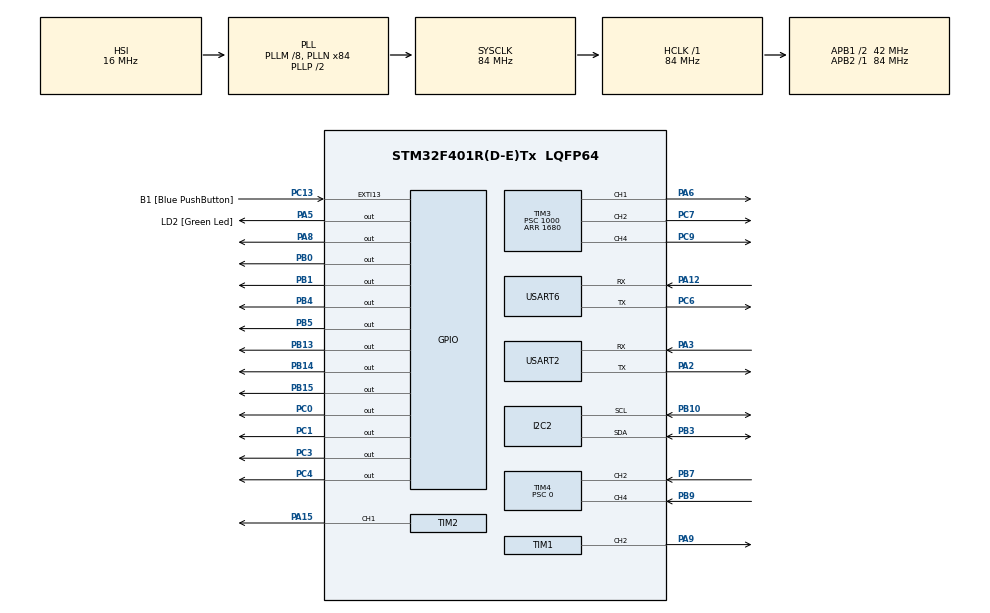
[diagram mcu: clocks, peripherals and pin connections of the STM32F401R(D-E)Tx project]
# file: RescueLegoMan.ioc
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Dma.Request0=TIM4_CH2
Dma.TIM4_CH2.0.Direction=DMA_PERIPH_TO_MEMORY
Dma.TIM4_CH2.0.FIFOMode=DMA_FIFOMODE_DISABLE
Dma.TIM4_CH2.0.Instance=DMA1_Stream3
Dma.TIM4_CH2.0.MemDataAlignment=DMA_MDATAALIGN_WORD
Dma.TIM4_CH2.0.MemInc=DMA_MINC_ENABLE
Dma.TIM4_CH2.0.Mode=DMA_NORMAL
Dma.TIM4_CH2.0.PeriphDataAlignment=DMA_PDATAALIGN_WORD
Dma.TIM4_CH2.0.PeriphInc=DMA_PINC_DISABLE
Dma.TIM4_CH2.0.Priority=DMA_PRIORITY_LOW
Mcu.Family=STM32F4
Mcu.Name=STM32F401R(D-E)Tx
Mcu.Package=LQFP64
NVIC.DMA1_Stream3_IRQn=true\:0\:0\:false\:false\:true\:false\:true
NVIC.EXTI15_10_IRQn=true\:0\:0\:false\:false\:true\:true\:true
NVIC.PriorityGroup=NVIC_PRIORITYGROUP_0
NVIC.TIM2_IRQn=true\:0\:0\:false\:false\:true\:true\:true
NVIC.TIM3_IRQn=true\:0\:0\:false\:false\:true\:true\:true
NVIC.TIM4_IRQn=true\:0\:0\:false\:false\:true\:true\:true
PA12.Mode=Asynchronous
PA12.Signal=USART6_RX
PA13.GPIO_Label=TMS
PA13.Mode=Serial_Wire
PA13.Signal=SYS_JTMS-SWDIO
PA14.GPIO_Label=TCK
PA14.Mode=Serial_Wire
PA14.Signal=SYS_JTCK-SWCLK
PA15.Signal=S_TIM2_CH1_ETR
PA2.Mode=Asynchronous
PA2.Signal=USART2_TX
PA3.Mode=Asynchronous
PA3.Signal=USART2_RX
PA5.GPIO_Label=LD2 [Green Led]
PA5.GPIO_Mode=GPIO_MODE_OUTPUT_PP
PA5.GPIO_PuPd=GPIO_NOPULL
PA5.GPIO_Speed=GPIO_SPEED_FREQ_LOW
PA5.Signal=GPIO_Output
PA6.Signal=S_TIM3_CH1
PA8.Signal=GPIO_Output
PA9.Signal=S_TIM1_CH2
PB0.Signal=GPIO_Output
PB1.Signal=GPIO_Output
PB10.Mode=I2C
PB10.Signal=I2C2_SCL
PB13.Signal=GPIO_Output
PB14.Signal=GPIO_Output
PB15.Signal=GPIO_Output
PB3.Mode=I2C
PB3.Signal=I2C2_SDA
PB4.Signal=GPIO_Output
PB5.Signal=GPIO_Output
PB7.Signal=S_TIM4_CH2
PB9.Signal=S_TIM4_CH4
PC0.Signal=GPIO_Output
PC1.Signal=GPIO_Output
PC13-ANTI_TAMP.GPIO_Label=B1 [Blue PushButton]
PC13-ANTI_TAMP.GPIO_ModeDefaultEXTI=GPIO_MODE_IT_FALLING
PC13-ANTI_TAMP.GPIO_PuPd=GPIO_NOPULL
PC13-ANTI_TAMP.Signal=GPXTI13
PC14-OSC32_IN.Mode=LSE-External-Oscillator
PC14-OSC32_IN.Signal=RCC_OSC32_IN
PC15-OSC32_OUT.Mode=LSE-External-Oscillator
PC15-OSC32_OUT.Signal=RCC_OSC32_OUT
PC3.Signal=GPIO_Output
PC4.Signal=GPIO_Output
PC6.Mode=Asynchronous
PC6.Signal=USART6_TX
PC7.Signal=S_TIM3_CH2
PC9.Signal=S_TIM3_CH4
PH0\ -\ OSC_IN.Mode=HSE-External-Clock-Source
PH0\ -\ OSC_IN.Signal=RCC_OSC_IN
PH1\ -\ OSC_OUT.Mode=HSE-External-Clock-Source
PH1\ -\ OSC_OUT.Signal=RCC_OSC_OUT
ProjectManager.HeapSize=0x200
ProjectManager.StackSize=0x400
ProjectManager.TargetToolchain=STM32CubeIDE
RCC.48MHZClocksFreq_Value=24000000
RCC.AHBFreq_Value=84000000
RCC.APB1CLKDivider=RCC_HCLK_DIV2
RCC.APB1Freq_Value=42000000
RCC.APB1TimFreq_Value=84000000
RCC.APB2Freq_Value=84000000
RCC.APB2TimFreq_Value=84000000
RCC.CortexFreq_Value=84000000
RCC.HCLKFreq_Value=84000000
RCC.HSE_VALUE=8000000
RCC.HSI_VALUE=16000000
RCC.PLLM=8
RCC.PLLN=84
RCC.PLLQ=7
RCC.SYSCLKFreq_VALUE=84000000
RCC.SYSCLKSource=RCC_SYSCLKSOURCE_PLLCLK
RCC.VCOOutputFreq_Value=168000000
SH.S_TIM1_CH2.0=TIM1_CH2,PWM Generation2 CH2
SH.S_TIM2_CH1_ETR.0=TIM2_CH1,PWM Generation1 CH1
SH.S_TIM3_CH1.0=TIM3_CH1,PWM Generation1 CH1
SH.S_TIM3_CH2.0=TIM3_CH2,PWM Generation2 CH2
SH.S_TIM3_CH4.0=TIM3_CH4,PWM Generation4 CH4
SH.S_TIM4_CH2.0=TIM4_CH2,Input_Capture2_from_TI2
SH.S_TIM4_CH4.0=TIM4_CH4,Input_Capture4_from_TI4
TIM1.AutoReloadPreload=TIM_AUTORELOAD_PRELOAD_ENABLE
TIM1.Channel-PWM\ Generation2\ CH2=TIM_CHANNEL_2
TIM1.Period=1680
TIM1.Prescaler=1000
TIM2.AutoReloadPreload=TIM_AUTORELOAD_PRELOAD_ENABLE
TIM2.Channel-PWM\ Generation1\ CH1=TIM_CHANNEL_1
TIM2.Period=1000
TIM2.Prescaler=1680
TIM3.AutoReloadPreload=TIM_AUTORELOAD_PRELOAD_ENABLE
TIM3.Channel-PWM\ Generation1\ CH1=TIM_CHANNEL_1
TIM3.Channel-PWM\ Generation2\ CH2=TIM_CHANNEL_2
TIM3.Channel-PWM\ Generation4\ CH4=TIM_CHANNEL_4
TIM3.Period=1680
TIM3.Prescaler=1000
TIM4.Channel-Input_Capture2_from_TI2=TIM_CHANNEL_2
TIM4.Channel-Input_Capture4_from_TI4=TIM_CHANNEL_4
TIM4.Period=0xffff
TIM4.Prescaler=0
USART2.VirtualMode=VM_ASYNC
USART6.VirtualMode=VM_ASYNC
VP_TIM2_VS_ClockSourceINT.Mode=Internal
board=NUCLEO-F401RE

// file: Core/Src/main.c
/* USER CODE BEGIN Header */
/**
  ******************************************************************************
  * @file           : main.c
  * @brief          : Main program body
  ******************************************************************************
  * @attention
  *
  * <h2><center>&copy; Copyright (c) 2021 STMicroelectronics.
  * All rights reserved.</center></h2>
  *
  * This software component is licensed by ST under BSD 3-Clause license,
  * the "License"; You may not use this file except in compliance with the
  * License. You may obtain a copy of the License at:
  *                        opensource.org/licenses/BSD-3-Clause
  *
  ******************************************************************************
  */
/* USER CODE END Header */
#include "main.h"

/* USER CODE BEGIN Includes */
#include <algorithm.h>
#include <colour_sensor.h>
#include <imu.h>
#include <motor.h>
#include <servo.h>
#include <test.h>

/* USER CODE END Includes */

I2C_HandleTypeDef hi2c2;

TIM_HandleTypeDef htim1;
TIM_HandleTypeDef htim2;
TIM_HandleTypeDef htim3;
TIM_HandleTypeDef htim4;
DMA_HandleTypeDef hdma_tim4_ch2;

UART_HandleTypeDef huart2;
UART_HandleTypeDef huart6;

void SystemClock_Config(void);
static void MX_GPIO_Init(void);
static void MX_USART2_UART_Init(void);
static void MX_TIM2_Init(void);
static void MX_TIM1_Init(void);
static void MX_TIM3_Init(void);
static void MX_TIM4_Init(void);
static void MX_USART6_UART_Init(void);
static void MX_DMA_Init(void);
static void MX_I2C2_Init(void);

int main(void)
{

  /* MCU Configuration--------------------------------------------------------*/

  /* Reset of all peripherals, Initializes the Flash interface and the Systick. */
  HAL_Init();

  /* Configure the system clock */
  SystemClock_Config();

  /* Initialize all configured peripherals */
  MX_GPIO_Init();
  MX_USART2_UART_Init();
  MX_TIM2_Init();
  MX_TIM1_Init();
  MX_TIM3_Init();
  MX_TIM4_Init();
  MX_USART6_UART_Init();
  MX_DMA_Init();
  MX_I2C2_Init();

  /* Infinite loop */
  /* USER CODE BEGIN WHILE */

//  initMotors(&htim1, &htim3);
//  initServo(&htim2);
//  initColourSensors(&htim4);
//  HAL_Delay(3000);
  init(&htim1, &htim3, &htim2, &htim4);
  searchAndRescue();

  while (1)
  {
    /* USER CODE END WHILE */

    /* USER CODE BEGIN 3 */
	  //testMotors();
//	  testServo();
	  //testImu(&hi2c2);
	  //testColourSensor();
  }
  /* USER CODE END 3 */
}

void SystemClock_Config(void)
{
  RCC_OscInitTypeDef RCC_OscInitStruct = {0};
  RCC_ClkInitTypeDef RCC_ClkInitStruct = {0};

  /** Configure the main internal regulator output voltage
  */
  __HAL_RCC_PWR_CLK_ENABLE();
  __HAL_PWR_VOLTAGESCALING_CONFIG(PWR_REGULATOR_VOLTAGE_SCALE2);
  /** Initializes the RCC Oscillators according to the specified parameters
  * in the RCC_OscInitTypeDef structure.
  */
  RCC_OscInitStruct.OscillatorType = RCC_OSCILLATORTYPE_HSI;
  RCC_OscInitStruct.HSIState = RCC_HSI_ON;
  RCC_OscInitStruct.HSICalibrationValue = RCC_HSICALIBRATION_DEFAULT;
  RCC_OscInitStruct.PLL.PLLState = RCC_PLL_ON;
  RCC_OscInitStruct.PLL.PLLSource = RCC_PLLSOURCE_HSI;
  RCC_OscInitStruct.PLL.PLLM = 8;
  RCC_OscInitStruct.PLL.PLLN = 84;
  RCC_OscInitStruct.PLL.PLLP = RCC_PLLP_DIV2;
  RCC_OscInitStruct.PLL.PLLQ = 7;
  if (HAL_RCC_OscConfig(&RCC_OscInitStruct) != HAL_OK)
  {
    Error_Handler();
  }
  /** Initializes the CPU, AHB and APB buses clocks
  */
  RCC_ClkInitStruct.ClockType = RCC_CLOCKTYPE_HCLK|RCC_CLOCKTYPE_SYSCLK
                              |RCC_CLOCKTYPE_PCLK1|RCC_CLOCKTYPE_PCLK2;
  RCC_ClkInitStruct.SYSCLKSource = RCC_SYSCLKSOURCE_PLLCLK;
  RCC_ClkInitStruct.AHBCLKDivider = RCC_SYSCLK_DIV1;
  RCC_ClkInitStruct.APB1CLKDivider = RCC_HCLK_DIV2;
  RCC_ClkInitStruct.APB2CLKDivider = RCC_HCLK_DIV1;

  if (HAL_RCC_ClockConfig(&RCC_ClkInitStruct, FLASH_LATENCY_2) != HAL_OK)
  {
    Error_Handler();
  }
}

static void MX_I2C2_Init(void)
{

  hi2c2.Instance = I2C2;
  hi2c2.Init.ClockSpeed = 100000;
  hi2c2.Init.DutyCycle = I2C_DUTYCYCLE_2;
  hi2c2.Init.OwnAddress1 = 0;
  hi2c2.Init.AddressingMode = I2C_ADDRESSINGMODE_7BIT;
  hi2c2.Init.DualAddressMode = I2C_DUALADDRESS_DISABLE;
  hi2c2.Init.OwnAddress2 = 0;
  hi2c2.Init.GeneralCallMode = I2C_GENERALCALL_DISABLE;
  hi2c2.Init.NoStretchMode = I2C_NOSTRETCH_DISABLE;
  if (HAL_I2C_Init(&hi2c2) != HAL_OK)
  {
    Error_Handler();
  }

}

static void MX_TIM1_Init(void)
{

  TIM_MasterConfigTypeDef sMasterConfig = {0};
  TIM_OC_InitTypeDef sConfigOC = {0};
  TIM_BreakDeadTimeConfigTypeDef sBreakDeadTimeConfig = {0};

  htim1.Instance = TIM1;
  htim1.Init.Prescaler = 1000;
  htim1.Init.CounterMode = TIM_COUNTERMODE_UP;
  htim1.Init.Period = 1680;
  htim1.Init.ClockDivision = TIM_CLOCKDIVISION_DIV1;
  htim1.Init.RepetitionCounter = 0;
  htim1.Init.AutoReloadPreload = TIM_AUTORELOAD_PRELOAD_ENABLE;
  if (HAL_TIM_PWM_Init(&htim1) != HAL_OK)
  {
    Error_Handler();
  }
  sMasterConfig.MasterOutputTrigger = TIM_TRGO_RESET;
  sMasterConfig.MasterSlaveMode = TIM_MASTERSLAVEMODE_DISABLE;
  if (HAL_TIMEx_MasterConfigSynchronization(&htim1, &sMasterConfig) != HAL_OK)
  {
    Error_Handler();
  }
  sConfigOC.OCMode = TIM_OCMODE_PWM1;
  sConfigOC.Pulse = 0;
  sConfigOC.OCPolarity = TIM_OCPOLARITY_HIGH;
  sConfigOC.OCNPolarity = TIM_OCNPOLARITY_HIGH;
  sConfigOC.OCFastMode = TIM_OCFAST_DISABLE;
  sConfigOC.OCIdleState = TIM_OCIDLESTATE_RESET;
  sConfigOC.OCNIdleState = TIM_OCNIDLESTATE_RESET;
  if (HAL_TIM_PWM_ConfigChannel(&htim1, &sConfigOC, TIM_CHANNEL_2) != HAL_OK)
  {
    Error_Handler();
  }
  sBreakDeadTimeConfig.OffStateRunMode = TIM_OSSR_DISABLE;
  sBreakDeadTimeConfig.OffStateIDLEMode = TIM_OSSI_DISABLE;
  sBreakDeadTimeConfig.LockLevel = TIM_LOCKLEVEL_OFF;
  sBreakDeadTimeConfig.DeadTime = 0;
  sBreakDeadTimeConfig.BreakState = TIM_BREAK_DISABLE;
  sBreakDeadTimeConfig.BreakPolarity = TIM_BREAKPOLARITY_HIGH;
  sBreakDeadTimeConfig.AutomaticOutput = TIM_AUTOMATICOUTPUT_DISABLE;
  if (HAL_TIMEx_ConfigBreakDeadTime(&htim1, &sBreakDeadTimeConfig) != HAL_OK)
  {
    Error_Handler();
  }
  HAL_TIM_MspPostInit(&htim1);

}

static void MX_TIM2_Init(void)
{

  TIM_ClockConfigTypeDef sClockSourceConfig = {0};
  TIM_MasterConfigTypeDef sMasterConfig = {0};
  TIM_OC_InitTypeDef sConfigOC = {0};

  htim2.Instance = TIM2;
  htim2.Init.Prescaler = 1680;
  htim2.Init.CounterMode = TIM_COUNTERMODE_UP;
  htim2.Init.Period = 1000;
  htim2.Init.ClockDivision = TIM_CLOCKDIVISION_DIV1;
  htim2.Init.AutoReloadPreload = TIM_AUTORELOAD_PRELOAD_ENABLE;
  if (HAL_TIM_Base_Init(&htim2) != HAL_OK)
  {
    Error_Handler();
  }
  sClockSourceConfig.ClockSource = TIM_CLOCKSOURCE_INTERNAL;
  if (HAL_TIM_ConfigClockSource(&htim2, &sClockSourceConfig) != HAL_OK)
  {
    Error_Handler();
  }
  if (HAL_TIM_PWM_Init(&htim2) != HAL_OK)
  {
    Error_Handler();
  }
  sMasterConfig.MasterOutputTrigger = TIM_TRGO_RESET;
  sMasterConfig.MasterSlaveMode = TIM_MASTERSLAVEMODE_DISABLE;
  if (HAL_TIMEx_MasterConfigSynchronization(&htim2, &sMasterConfig) != HAL_OK)
  {
    Error_Handler();
  }
  sConfigOC.OCMode = TIM_OCMODE_PWM1;
  sConfigOC.Pulse = 0;
  sConfigOC.OCPolarity = TIM_OCPOLARITY_HIGH;
  sConfigOC.OCFastMode = TIM_OCFAST_DISABLE;
  if (HAL_TIM_PWM_ConfigChannel(&htim2, &sConfigOC, TIM_CHANNEL_1) != HAL_OK)
  {
    Error_Handler();
  }
  HAL_TIM_MspPostInit(&htim2);

}

static void MX_TIM3_Init(void)
{

  TIM_MasterConfigTypeDef sMasterConfig = {0};
  TIM_OC_InitTypeDef sConfigOC = {0};

  htim3.Instance = TIM3;
  htim3.Init.Prescaler = 1000;
  htim3.Init.CounterMode = TIM_COUNTERMODE_UP;
  htim3.Init.Period = 1680;
  htim3.Init.ClockDivision = TIM_CLOCKDIVISION_DIV1;
  htim3.Init.AutoReloadPreload = TIM_AUTORELOAD_PRELOAD_ENABLE;
  if (HAL_TIM_PWM_Init(&htim3) != HAL_OK)
  {
    Error_Handler();
  }
  sMasterConfig.MasterOutputTrigger = TIM_TRGO_RESET;
  sMasterConfig.MasterSlaveMode = TIM_MASTERSLAVEMODE_DISABLE;
  if (HAL_TIMEx_MasterConfigSynchronization(&htim3, &sMasterConfig) != HAL_OK)
  {
    Error_Handler();
  }
  sConfigOC.OCMode = TIM_OCMODE_PWM1;
  sConfigOC.Pulse = 0;
  sConfigOC.OCPolarity = TIM_OCPOLARITY_HIGH;
  sConfigOC.OCFastMode = TIM_OCFAST_DISABLE;
  if (HAL_TIM_PWM_ConfigChannel(&htim3, &sConfigOC, TIM_CHANNEL_1) != HAL_OK)
  {
    Error_Handler();
  }
  if (HAL_TIM_PWM_ConfigChannel(&htim3, &sConfigOC, TIM_CHANNEL_2) != HAL_OK)
  {
    Error_Handler();
  }
  if (HAL_TIM_PWM_ConfigChannel(&htim3, &sConfigOC, TIM_CHANNEL_4) != HAL_OK)
  {
    Error_Handler();
  }
  HAL_TIM_MspPostInit(&htim3);

}

static void MX_TIM4_Init(void)
{

  TIM_MasterConfigTypeDef sMasterConfig = {0};
  TIM_IC_InitTypeDef sConfigIC = {0};

  htim4.Instance = TIM4;
  htim4.Init.Prescaler = 0;
  htim4.Init.CounterMode = TIM_COUNTERMODE_UP;
  htim4.Init.Period = 0xffff;
  htim4.Init.ClockDivision = TIM_CLOCKDIVISION_DIV1;
  htim4.Init.AutoReloadPreload = TIM_AUTORELOAD_PRELOAD_DISABLE;
  if (HAL_TIM_IC_Init(&htim4) != HAL_OK)
  {
    Error_Handler();
  }
  sMasterConfig.MasterOutputTrigger = TIM_TRGO_RESET;
  sMasterConfig.MasterSlaveMode = TIM_MASTERSLAVEMODE_DISABLE;
  if (HAL_TIMEx_MasterConfigSynchronization(&htim4, &sMasterConfig) != HAL_OK)
  {
    Error_Handler();
  }
  sConfigIC.ICPolarity = TIM_INPUTCHANNELPOLARITY_RISING;
  sConfigIC.ICSelection = TIM_ICSELECTION_DIRECTTI;
  sConfigIC.ICPrescaler = TIM_ICPSC_DIV1;
  sConfigIC.ICFilter = 0;
  if (HAL_TIM_IC_ConfigChannel(&htim4, &sConfigIC, TIM_CHANNEL_2) != HAL_OK)
  {
    Error_Handler();
  }
  if (HAL_TIM_IC_ConfigChannel(&htim4, &sConfigIC, TIM_CHANNEL_4) != HAL_OK)
  {
    Error_Handler();
  }

}

static void MX_USART2_UART_Init(void)
{

  huart2.Instance = USART2;
  huart2.Init.BaudRate = 115200;
  huart2.Init.WordLength = UART_WORDLENGTH_8B;
  huart2.Init.StopBits = UART_STOPBITS_1;
  huart2.Init.Parity = UART_PARITY_NONE;
  huart2.Init.Mode = UART_MODE_TX_RX;
  huart2.Init.HwFlowCtl = UART_HWCONTROL_NONE;
  huart2.Init.OverSampling = UART_OVERSAMPLING_16;
  if (HAL_UART_Init(&huart2) != HAL_OK)
  {
    Error_Handler();
  }

}

static void MX_USART6_UART_Init(void)
{

  huart6.Instance = USART6;
  huart6.Init.BaudRate = 115200;
  huart6.Init.WordLength = UART_WORDLENGTH_8B;
  huart6.Init.StopBits = UART_STOPBITS_1;
  huart6.Init.Parity = UART_PARITY_NONE;
  huart6.Init.Mode = UART_MODE_TX_RX;
  huart6.Init.HwFlowCtl = UART_HWCONTROL_NONE;
  huart6.Init.OverSampling = UART_OVERSAMPLING_16;
  if (HAL_UART_Init(&huart6) != HAL_OK)
  {
    Error_Handler();
  }

}

static void MX_DMA_Init(void)
{

  /* DMA controller clock enable */
  __HAL_RCC_DMA1_CLK_ENABLE();

  /* DMA interrupt init */
  /* DMA1_Stream3_IRQn interrupt configuration */
  HAL_NVIC_SetPriority(DMA1_Stream3_IRQn, 0, 0);
  HAL_NVIC_EnableIRQ(DMA1_Stream3_IRQn);

}

static void MX_GPIO_Init(void)
{
  GPIO_InitTypeDef GPIO_InitStruct = {0};

  /* GPIO Ports Clock Enable */
  __HAL_RCC_GPIOC_CLK_ENABLE();
  __HAL_RCC_GPIOH_CLK_ENABLE();
  __HAL_RCC_GPIOA_CLK_ENABLE();
  __HAL_RCC_GPIOB_CLK_ENABLE();

  /*Configure GPIO pin Output Level */
  HAL_GPIO_WritePin(GPIOC, GPIO_PIN_0|GPIO_PIN_1|GPIO_PIN_3|GPIO_PIN_4, GPIO_PIN_RESET);

  /*Configure GPIO pin Output Level */
  HAL_GPIO_WritePin(GPIOA, LD2_Pin|GPIO_PIN_8, GPIO_PIN_RESET);

  /*Configure GPIO pin Output Level */
  HAL_GPIO_WritePin(GPIOB, GPIO_PIN_0|GPIO_PIN_1|GPIO_PIN_13|GPIO_PIN_14
                          |GPIO_PIN_15|GPIO_PIN_4|GPIO_PIN_5, GPIO_PIN_RESET);

  /*Configure GPIO pin : B1_Pin */
  GPIO_InitStruct.Pin = B1_Pin;
  GPIO_InitStruct.Mode = GPIO_MODE_IT_FALLING;
  GPIO_InitStruct.Pull = GPIO_NOPULL;
  HAL_GPIO_Init(B1_GPIO_Port, &GPIO_InitStruct);

  /*Configure GPIO pins : PC0 PC1 PC3 PC4 */
  GPIO_InitStruct.Pin = GPIO_PIN_0|GPIO_PIN_1|GPIO_PIN_3|GPIO_PIN_4;
  GPIO_InitStruct.Mode = GPIO_MODE_OUTPUT_PP;
  GPIO_InitStruct.Pull = GPIO_NOPULL;
  GPIO_InitStruct.Speed = GPIO_SPEED_FREQ_LOW;
  HAL_GPIO_Init(GPIOC, &GPIO_InitStruct);

  /*Configure GPIO pins : LD2_Pin PA8 */
  GPIO_InitStruct.Pin = LD2_Pin|GPIO_PIN_8;
  GPIO_InitStruct.Mode = GPIO_MODE_OUTPUT_PP;
  GPIO_InitStruct.Pull = GPIO_NOPULL;
  GPIO_InitStruct.Speed = GPIO_SPEED_FREQ_LOW;
  HAL_GPIO_Init(GPIOA, &GPIO_InitStruct);

  /*Configure GPIO pins : PB0 PB1 PB13 PB14
                           PB15 PB4 PB5 */
  GPIO_InitStruct.Pin = GPIO_PIN_0|GPIO_PIN_1|GPIO_PIN_13|GPIO_PIN_14
                          |GPIO_PIN_15|GPIO_PIN_4|GPIO_PIN_5;
  GPIO_InitStruct.Mode = GPIO_MODE_OUTPUT_PP;
  GPIO_InitStruct.Pull = GPIO_NOPULL;
  GPIO_InitStruct.Speed = GPIO_SPEED_FREQ_LOW;
  HAL_GPIO_Init(GPIOB, &GPIO_InitStruct);

  /* EXTI interrupt init*/
  HAL_NVIC_SetPriority(EXTI15_10_IRQn, 0, 0);
  HAL_NVIC_EnableIRQ(EXTI15_10_IRQn);

}

void Error_Handler(void)
{
  __disable_irq();
  while (1)
  {
  }
}

/************************ (C) COPYRIGHT STMicroelectronics *****END OF FILE****/
